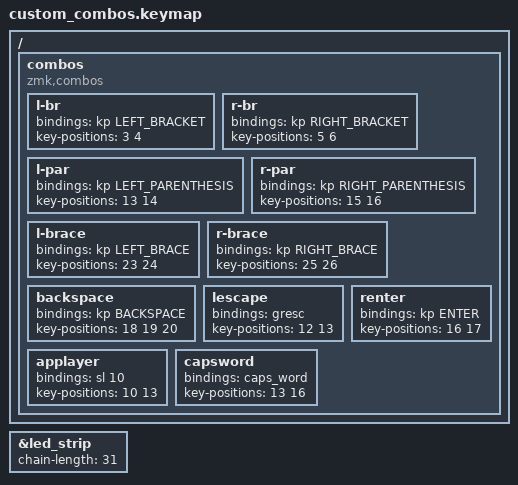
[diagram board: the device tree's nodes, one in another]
#include <behaviors.dtsi>
#include <dt-bindings/zmk/bt.h>
#include <dt-bindings/zmk/ext_power.h>
#include <dt-bindings/zmk/keys.h>
#include <dt-bindings/zmk/outputs.h>
#include <dt-bindings/zmk/rgb.h>

&led_strip {
	chain-length = <31>;
};


/ {
	combos {
		compatible = "zmk,combos";
		
		l-br {
			bindings = <&kp LEFT_BRACKET>;
			key-positions = <3 4>;
		};
		
		r-br {
			bindings = <&kp RIGHT_BRACKET>;
			key-positions = <5 6>;
		};
		
		l-par {
			bindings = <&kp LEFT_PARENTHESIS>;
			key-positions = <13 14>;
		};
		
		r-par {
			bindings = <&kp RIGHT_PARENTHESIS>;
			key-positions = <15 16>;
		};
		
		l-brace {
			bindings = <&kp LEFT_BRACE>;
			key-positions = <23 24>;
		};
		
		r-brace {
			bindings = <&kp RIGHT_BRACE>;
			key-positions = <25 26>;
		};
		
		backspace {
			bindings = <&kp BACKSPACE>;
			key-positions = <18 19 20>;
		};
		
		lescape {
			bindings = <&gresc>;
			key-positions = <12 13>;
		};
		
		renter {
			bindings = <&kp ENTER>;
			key-positions = <16 17>;
		};
		
		applayer {
			bindings = <&sl 10>;
			key-positions = <10 13>;
		};
		
		capsword {
			bindings = <&caps_word>;
			key-positions = <13 16>;
		};
	};
	
};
